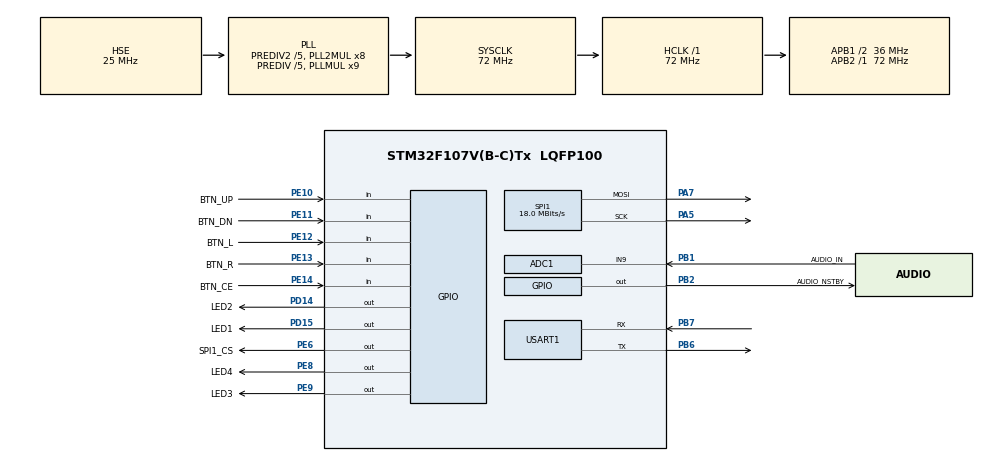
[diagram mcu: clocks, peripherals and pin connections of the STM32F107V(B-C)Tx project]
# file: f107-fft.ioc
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ADC1.Channel-8\#ChannelRegularConversion=ADC_CHANNEL_9
ADC1.ContinuousConvMode=DISABLE
ADC1.DataAlign=ADC_DATAALIGN_RIGHT
ADC1.DiscontinuousConvMode=DISABLE
ADC1.EnableAnalogWatchDog=false
ADC1.EnableRegularConversion=ENABLE
ADC1.ExternalTrigConv=ADC_EXTERNALTRIGCONV_T3_TRGO
ADC1.ExternalTrigConvEdgeChoice=RISING
ADC1.InjNumberOfConversion=0
ADC1.NbrOfConversion=1
ADC1.NbrOfConversionFlag=1
ADC1.Rank-8\#ChannelRegularConversion=1
ADC1.SamplingTime-8\#ChannelRegularConversion=ADC_SAMPLETIME_7CYCLES_5
ADC1.ScanConvMode=ADC_SCAN_DISABLE
ADC1.master=1
Dma.ADC1.0.Direction=DMA_PERIPH_TO_MEMORY
Dma.ADC1.0.Instance=DMA1_Channel1
Dma.ADC1.0.MemDataAlignment=DMA_MDATAALIGN_WORD
Dma.ADC1.0.MemInc=DMA_MINC_ENABLE
Dma.ADC1.0.Mode=DMA_NORMAL
Dma.ADC1.0.PeriphDataAlignment=DMA_PDATAALIGN_WORD
Dma.ADC1.0.PeriphInc=DMA_PINC_DISABLE
Dma.ADC1.0.Priority=DMA_PRIORITY_MEDIUM
Dma.Request0=ADC1
Mcu.Family=STM32F1
Mcu.Name=STM32F107V(B-C)Tx
Mcu.Package=LQFP100
NVIC.DMA1_Channel1_IRQn=true\:0\:0\:false\:false\:true
NVIC.PriorityGroup=NVIC_PRIORITYGROUP_4
OSC_IN.Mode=HSE-External-Oscillator
OSC_IN.Signal=RCC_OSC_IN
OSC_OUT.Mode=HSE-External-Oscillator
OSC_OUT.Signal=RCC_OSC_OUT
PA5.Mode=TX_Only_Simplex_Unidirect_Master
PA5.Signal=SPI1_SCK
PA7.Mode=TX_Only_Simplex_Unidirect_Master
PA7.Signal=SPI1_MOSI
PB1.GPIO_Label=AUDIO_IN
PB1.Signal=ADCx_IN9
PB2.GPIO_Label=AUDIO_NSTBY
PB2.Signal=GPIO_Output
PB6.Mode=Asynchronous
PB6.Signal=USART1_TX
PB7.Mode=Asynchronous
PB7.Signal=USART1_RX
PD14.GPIO_Label=LED2
PD14.Signal=GPIO_Output
PD15.GPIO_Label=LED1
PD15.Signal=GPIO_Output
PE10.GPIO_Label=BTN_UP
PE10.Signal=GPIO_Input
PE11.GPIO_Label=BTN_DN
PE11.Signal=GPIO_Input
PE12.GPIO_Label=BTN_L
PE12.Signal=GPIO_Input
PE13.GPIO_Label=BTN_R
PE13.Signal=GPIO_Input
PE14.GPIO_Label=BTN_CE
PE14.Signal=GPIO_Input
PE6.GPIO_Label=SPI1_CS
PE6.Signal=GPIO_Output
PE8.GPIO_Label=LED4
PE8.Signal=GPIO_Output
PE9.GPIO_Label=LED3
PE9.Signal=GPIO_Output
ProjectManager.HeapSize=0x200
ProjectManager.StackSize=0x400
ProjectManager.TargetToolchain=SW4STM32
RCC.ADCPresc=RCC_ADCPCLK2_DIV6
RCC.AHBFreq_Value=72000000
RCC.APB1CLKDivider=RCC_HCLK_DIV2
RCC.APB1Freq_Value=36000000
RCC.APB1TimFreq_Value=72000000
RCC.APB2Freq_Value=72000000
RCC.APB2TimFreq_Value=72000000
RCC.HCLKFreq_Value=72000000
RCC.HSEDivPLL=RCC_HSE_PREDIV_DIV5
RCC.HSE_VALUE=25000000
RCC.HSIState=RCC_HSI_ON
RCC.PLLMUL=RCC_PLL_MUL9
RCC.PLLSourceVirtual=RCC_PLLSOURCE_HSE
RCC.Prediv1Source=RCC_PREDIV1_SOURCE_PLL2
RCC.Prediv2=RCC_HSE_PREDIV2_DIV5
RCC.SYSCLKFreq_VALUE=72000000
RCC.SYSCLKSource=RCC_SYSCLKSOURCE_PLLCLK
RCC.USBFreq_Value=48000000
SH.ADCx_IN9.0=ADC1_IN9,IN9
SPI1.BaudRatePrescaler=SPI_BAUDRATEPRESCALER_4
SPI1.CalculateBaudRate=18.0 MBits/s
SPI1.Mode=SPI_MODE_MASTER
TIM3.Period=1800
TIM3.TIM_MasterOutputTrigger=TIM_TRGO_UPDATE
TIM3.TIM_MasterSlaveMode=TIM_MASTERSLAVEMODE_DISABLE
VP_SYS_VS_ND.Mode=No_Debug
VP_TIM3_VS_no_output1.Mode=Output Compare1 No Output
board=f107-fft

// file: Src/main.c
/**
  ******************************************************************************
  * File Name          : main.c
  * Description        : Main program body
  ******************************************************************************
  *
  * COPYRIGHT(c) 2016 STMicroelectronics
  *
  * Redistribution and use in source and binary forms, with or without modification,
  * are permitted provided that the following conditions are met:
  *   1. Redistributions of source code must retain the above copyright notice,
  *      this list of conditions and the following disclaimer.
  *   2. Redistributions in binary form must reproduce the above copyright notice,
  *      this list of conditions and the following disclaimer in the documentation
  *      and/or other materials provided with the distribution.
  *   3. Neither the name of STMicroelectronics nor the names of its contributors
  *      may be used to endorse or promote products derived from this software
  *      without specific prior written permission.
  *
  * THIS SOFTWARE IS PROVIDED BY THE COPYRIGHT HOLDERS AND CONTRIBUTORS "AS IS"
  * AND ANY EXPRESS OR IMPLIED WARRANTIES, INCLUDING, BUT NOT LIMITED TO, THE
  * IMPLIED WARRANTIES OF MERCHANTABILITY AND FITNESS FOR A PARTICULAR PURPOSE ARE
  * DISCLAIMED. IN NO EVENT SHALL THE COPYRIGHT HOLDER OR CONTRIBUTORS BE LIABLE
  * FOR ANY DIRECT, INDIRECT, INCIDENTAL, SPECIAL, EXEMPLARY, OR CONSEQUENTIAL
  * DAMAGES (INCLUDING, BUT NOT LIMITED TO, PROCUREMENT OF SUBSTITUTE GOODS OR
  * SERVICES; LOSS OF USE, DATA, OR PROFITS; OR BUSINESS INTERRUPTION) HOWEVER
  * CAUSED AND ON ANY THEORY OF LIABILITY, WHETHER IN CONTRACT, STRICT LIABILITY,
  * OR TORT (INCLUDING NEGLIGENCE OR OTHERWISE) ARISING IN ANY WAY OUT OF THE USE
  * OF THIS SOFTWARE, EVEN IF ADVISED OF THE POSSIBILITY OF SUCH DAMAGE.
  *
  ******************************************************************************
  */
#include "stm32f1xx_hal.h"
#include "adc.h"
#include "dma.h"
#include "spi.h"
#include "tim.h"
#include "usart.h"
#include "gpio.h"

/* USER CODE BEGIN Includes */
#include "user_main.h"
/* USER CODE END Includes */

/* USER CODE BEGIN PV */
/* Private variables ---------------------------------------------------------*/

/* USER CODE END PV */

void SystemClock_Config(void);
void Error_Handler(void);

/* USER CODE BEGIN PFP */
/* Private function prototypes -----------------------------------------------*/

/* USER CODE END PFP */

int main(void)
{

  /* MCU Configuration----------------------------------------------------------*/

  /* Reset of all peripherals, Initializes the Flash interface and the Systick. */
  HAL_Init();

  /* Configure the system clock */
  SystemClock_Config();

  /* Initialize all configured peripherals */
  MX_GPIO_Init();
  MX_DMA_Init();
  MX_ADC1_Init();
  MX_SPI1_Init();
  MX_TIM3_Init();
  MX_USART1_UART_Init();

  /* Infinite loop */

  /* USER CODE BEGIN 3 */
  user_main();
  /* USER CODE END 3 */

}

/** System Clock Configuration
*/
void SystemClock_Config(void)
{

  RCC_OscInitTypeDef RCC_OscInitStruct;
  RCC_ClkInitTypeDef RCC_ClkInitStruct;
  RCC_PeriphCLKInitTypeDef PeriphClkInit;

  RCC_OscInitStruct.OscillatorType = RCC_OSCILLATORTYPE_HSE;
  RCC_OscInitStruct.HSEState = RCC_HSE_ON;
  RCC_OscInitStruct.HSEPredivValue = RCC_HSE_PREDIV_DIV5;
  RCC_OscInitStruct.Prediv1Source = RCC_PREDIV1_SOURCE_PLL2;
  RCC_OscInitStruct.PLL.PLLState = RCC_PLL_ON;
  RCC_OscInitStruct.PLL.PLLSource = RCC_PLLSOURCE_HSE;
  RCC_OscInitStruct.PLL.PLLMUL = RCC_PLL_MUL9;
  RCC_OscInitStruct.PLL2.PLL2State = RCC_PLL2_ON;
  RCC_OscInitStruct.PLL2.PLL2MUL = RCC_PLL2_MUL8;
  RCC_OscInitStruct.PLL2.HSEPrediv2Value = RCC_HSE_PREDIV2_DIV5;
  if (HAL_RCC_OscConfig(&RCC_OscInitStruct) != HAL_OK)
  {
    Error_Handler();
  }

  RCC_ClkInitStruct.ClockType = RCC_CLOCKTYPE_HCLK|RCC_CLOCKTYPE_SYSCLK
                              |RCC_CLOCKTYPE_PCLK1|RCC_CLOCKTYPE_PCLK2;
  RCC_ClkInitStruct.SYSCLKSource = RCC_SYSCLKSOURCE_PLLCLK;
  RCC_ClkInitStruct.AHBCLKDivider = RCC_SYSCLK_DIV1;
  RCC_ClkInitStruct.APB1CLKDivider = RCC_HCLK_DIV2;
  RCC_ClkInitStruct.APB2CLKDivider = RCC_HCLK_DIV1;
  if (HAL_RCC_ClockConfig(&RCC_ClkInitStruct, FLASH_LATENCY_2) != HAL_OK)
  {
    Error_Handler();
  }

  PeriphClkInit.PeriphClockSelection = RCC_PERIPHCLK_ADC;
  PeriphClkInit.AdcClockSelection = RCC_ADCPCLK2_DIV6;
  if (HAL_RCCEx_PeriphCLKConfig(&PeriphClkInit) != HAL_OK)
  {
    Error_Handler();
  }

  HAL_SYSTICK_Config(HAL_RCC_GetHCLKFreq()/1000);

  HAL_SYSTICK_CLKSourceConfig(SYSTICK_CLKSOURCE_HCLK);

  __HAL_RCC_PLLI2S_ENABLE();

  /* SysTick_IRQn interrupt configuration */
  HAL_NVIC_SetPriority(SysTick_IRQn, 0, 0);
}

void Error_Handler(void)
{
  /* USER CODE BEGIN Error_Handler */
  /* User can add his own implementation to report the HAL error return state */
  user_Error_Handler();
  /* USER CODE END Error_Handler */
}

#ifdef USE_FULL_ASSERT

/**
   * @brief Reports the name of the source file and the source line number
   * where the assert_param error has occurred.
   * @param file: pointer to the source file name
   * @param line: assert_param error line source number
   * @retval None
   */
void assert_failed(uint8_t* file, uint32_t line)
{
  /* USER CODE BEGIN 6 */
  /* User can add his own implementation to report the file name and line number,
    ex: printf("Wrong parameters value: file %s on line %d\r\n", file, line) */

  user_assert_failed(file, line);

  /* USER CODE END 6 */

}

#endif

/************************ (C) COPYRIGHT STMicroelectronics *****END OF FILE****/
